VERSION ""

NS_ :

BS_:

BU_: ECU1 ECU2 ECU3

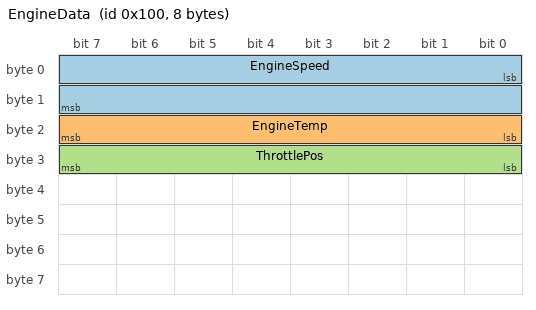
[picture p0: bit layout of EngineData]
BO_ 256 EngineData: 8 ECU1
 SG_ EngineSpeed : 0|16@1+ (0.25,0) [0|16383.75] "rpm" ECU2
 SG_ EngineTemp : 16|8@1+ (1,-40) [-40|215] "degC" ECU2
 SG_ ThrottlePos : 24|8@1+ (0.392157,0) [0|100] "%" ECU2

BO_ 512 VehicleSpeed: 8 ECU1
 SG_ Speed : 0|16@1+ (0.01,0) [0|655.35] "km/h" ECU2
 SG_ Odometer : 16|32@1+ (0.1,0) [0|429496729.5] "km" ECU2

BO_ 768 BrakeStatus: 4 ECU2
 SG_ BrakePressure : 0|16@1+ (0.1,0) [0|6553.5] "bar" ECU1
 SG_ ABSActive : 16|1@1+ (1,0) [0|1] "" ECU1

CM_ BU_ ECU1 "Engine Control Unit";
CM_ BU_ ECU2 "Body Control Unit";
CM_ BU_ ECU3 "Transmission Control Unit";
CM_ BO_ 256 "Engine data including speed, temperature, and throttle position";
CM_ BO_ 512 "Vehicle speed and odometer reading";
CM_ BO_ 768 "Brake system status";
CM_ SG_ 256 EngineSpeed "Engine rotational speed";
CM_ SG_ 256 EngineTemp "Engine coolant temperature";
CM_ SG_ 512 Speed "Vehicle speed";

VAL_ 768 ABSActive 0 "Inactive" 1 "Active";
